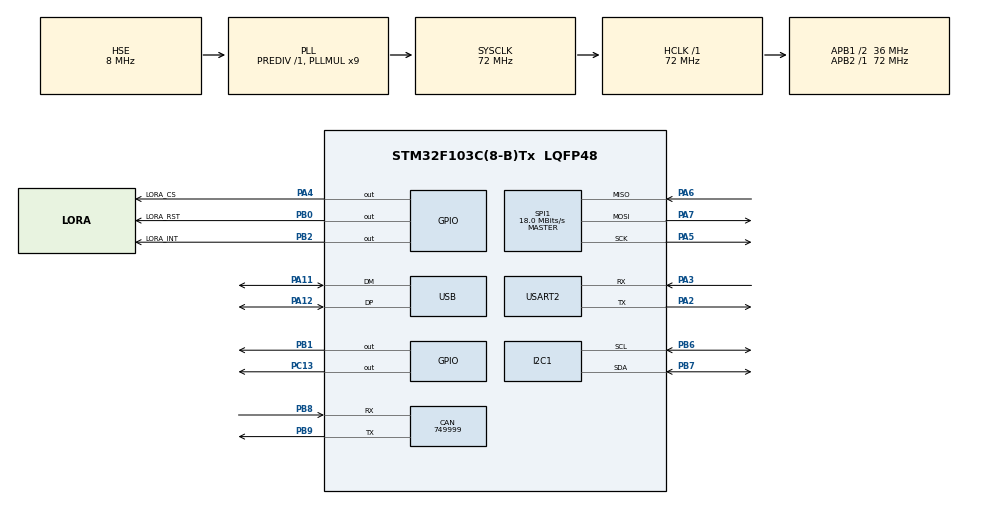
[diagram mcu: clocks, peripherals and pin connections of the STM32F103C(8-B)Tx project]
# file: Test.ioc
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CAN.CalculateBaudRate=749999
CAN.CalculateTimeBit=1333
CAN.CalculateTimeQuantum=444.44444444444446
FREERTOS.Tasks01=defaultTask,0,128,StartDefaultTask,Default,NULL,Dynamic,NULL,NULL
Mcu.Family=STM32F1
Mcu.Name=STM32F103C(8-B)Tx
Mcu.Package=LQFP48
NVIC.PriorityGroup=NVIC_PRIORITYGROUP_4
NVIC.TIM1_UP_IRQn=true\:15\:0\:false\:false\:true\:false\:false\:true\:true
NVIC.TimeBase=TIM1_UP_IRQn
NVIC.TimeBaseIP=TIM1
NVIC.USB_LP_CAN1_RX0_IRQn=true\:5\:0\:false\:false\:true\:true\:false\:true\:true
PA11.Mode=Device
PA11.Signal=USB_DM
PA12.Mode=Device
PA12.Signal=USB_DP
PA13.Mode=Serial_Wire
PA13.Signal=SYS_JTMS-SWDIO
PA14.Mode=Serial_Wire
PA14.Signal=SYS_JTCK-SWCLK
PA2.Mode=Asynchronous
PA2.Signal=USART2_TX
PA3.Mode=Asynchronous
PA3.Signal=USART2_RX
PA4.GPIO_Label=LORA_CS
PA4.Signal=GPIO_Output
PA5.Mode=Full_Duplex_Master
PA5.Signal=SPI1_SCK
PA6.Mode=Full_Duplex_Master
PA6.Signal=SPI1_MISO
PA7.Mode=Full_Duplex_Master
PA7.Signal=SPI1_MOSI
PB0.GPIO_Label=LORA_RST
PB0.Signal=GPIO_Output
PB1.Signal=GPIO_Output
PB2.GPIO_Label=LORA_INT
PB2.Signal=GPIO_Output
PB6.Mode=I2C
PB6.Signal=I2C1_SCL
PB7.Mode=I2C
PB7.Signal=I2C1_SDA
PB8.Mode=CAN_Activate
PB8.Signal=CAN_RX
PB9.Mode=CAN_Activate
PB9.Signal=CAN_TX
PC13-TAMPER-RTC.Signal=GPIO_Output
PD0-OSC_IN.Mode=HSE-External-Oscillator
PD0-OSC_IN.Signal=RCC_OSC_IN
PD1-OSC_OUT.Mode=HSE-External-Oscillator
PD1-OSC_OUT.Signal=RCC_OSC_OUT
ProjectManager.HeapSize=0x200
ProjectManager.StackSize=0x400
ProjectManager.TargetToolchain=STM32CubeIDE
RCC.AHBFreq_Value=72000000
RCC.APB1CLKDivider=RCC_HCLK_DIV2
RCC.APB1Freq_Value=36000000
RCC.APB1TimFreq_Value=72000000
RCC.APB2Freq_Value=72000000
RCC.APB2TimFreq_Value=72000000
RCC.HCLKFreq_Value=72000000
RCC.PLLMUL=RCC_PLL_MUL9
RCC.SYSCLKFreq_VALUE=72000000
RCC.SYSCLKSource=RCC_SYSCLKSOURCE_PLLCLK
RCC.USBFreq_Value=48000000
RCC.USBPrescaler=RCC_USBCLKSOURCE_PLL_DIV1_5
SPI1.BaudRatePrescaler=SPI_BAUDRATEPRESCALER_4
SPI1.CalculateBaudRate=18.0 MBits/s
SPI1.Direction=SPI_DIRECTION_2LINES
SPI1.Mode=SPI_MODE_MASTER
SPI1.VirtualType=VM_MASTER
USART2.VirtualMode=VM_ASYNC
USB_DEVICE.CLASS_NAME_FS=CDC
USB_DEVICE.VirtualMode=Cdc
USB_DEVICE.VirtualModeFS=Cdc_FS
VP_FREERTOS_VS_CMSIS_V1.Mode=CMSIS_V1
VP_SYS_VS_tim1.Mode=TIM1
VP_USB_DEVICE_VS_USB_DEVICE_CDC_FS.Mode=CDC_FS
board=custom

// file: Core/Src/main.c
/* USER CODE BEGIN Header */
/**
  ******************************************************************************
  * @file           : main.c
  * @brief          : Main program body
  ******************************************************************************
  * @attention
  *
  * Copyright (c) 2023 STMicroelectronics.
  * All rights reserved.
  *
  * This software is licensed under terms that can be found in the LICENSE file
  * in the root directory of this software component.
  * If no LICENSE file comes with this software, it is provided AS-IS.
  *
  ******************************************************************************
  */
/* USER CODE END Header */
#include "main.h"
#include "cmsis_os.h"
#include "usb_device.h"

CAN_HandleTypeDef hcan;

I2C_HandleTypeDef hi2c1;

SPI_HandleTypeDef hspi1;

UART_HandleTypeDef huart2;

osThreadId defaultTaskHandle;

void SystemClock_Config(void);
static void MX_GPIO_Init(void);
static void MX_CAN_Init(void);
static void MX_I2C1_Init(void);
static void MX_SPI1_Init(void);
static void MX_USART2_UART_Init(void);
void StartDefaultTask(void const * argument);

/* USER CODE BEGIN 0 */
uint8_t data[10000];
uint8_t count=0;
void HAL_UART_TxCpltCallback(UART_HandleTypeDef *huart)
{
	//HAL_UART_Transmit_IT(huart, data, sizeof(data));
}
/* USER CODE END 0 */

int main(void)
{

  /* MCU Configuration--------------------------------------------------------*/

  /* Reset of all peripherals, Initializes the Flash interface and the Systick. */
  HAL_Init();

  /* Configure the system clock */
  SystemClock_Config();

  /* Initialize all configured peripherals */
  MX_GPIO_Init();
  MX_CAN_Init();
  MX_I2C1_Init();
  MX_SPI1_Init();
  MX_USART2_UART_Init();
  /* USER CODE BEGIN 2 */
  //data[0] = "HELLO WORLD\r\n";
  for(int i = 0;i<10000;i++)
  {
	  data[i] = 'x';
  }
  HAL_UART_Transmit_IT(&huart1,data, sizeof(data));
  /* USER CODE END 2 */

  /* Create the thread(s) */
  /* definition and creation of defaultTask */
  osThreadDef(defaultTask, StartDefaultTask, osPriorityNormal, 0, 128);
  defaultTaskHandle = osThreadCreate(osThread(defaultTask), NULL);

  /* Start scheduler */
  osKernelStart();

  /* We should never get here as control is now taken by the scheduler */
  /* Infinite loop */
  while (1)
  {

    /* USER CODE BEGIN 3 */
	  HAL_GPIO_TogglePin(GPIOC, GPIO_PIN_13);
	  HAL_Delay(250);
	  count++ ;
	  if((count%20)==0)
		  HAL_UART_Transmit_IT(&huart1, data, sizeof(data));
  }
  /* USER CODE END 3 */
}

void SystemClock_Config(void)
{
  RCC_OscInitTypeDef RCC_OscInitStruct = {0};
  RCC_ClkInitTypeDef RCC_ClkInitStruct = {0};
  RCC_PeriphCLKInitTypeDef PeriphClkInit = {0};

  /** Initializes the RCC Oscillators according to the specified parameters
  * in the RCC_OscInitTypeDef structure.
  */
  RCC_OscInitStruct.OscillatorType = RCC_OSCILLATORTYPE_HSE;
  RCC_OscInitStruct.HSEState = RCC_HSE_ON;
  RCC_OscInitStruct.HSEPredivValue = RCC_HSE_PREDIV_DIV1;
  RCC_OscInitStruct.HSIState = RCC_HSI_ON;
  RCC_OscInitStruct.PLL.PLLState = RCC_PLL_ON;
  RCC_OscInitStruct.PLL.PLLSource = RCC_PLLSOURCE_HSE;
  RCC_OscInitStruct.PLL.PLLMUL = RCC_PLL_MUL9;
  if (HAL_RCC_OscConfig(&RCC_OscInitStruct) != HAL_OK)
  {
    Error_Handler();
  }

  /** Initializes the CPU, AHB and APB buses clocks
  */
  RCC_ClkInitStruct.ClockType = RCC_CLOCKTYPE_HCLK|RCC_CLOCKTYPE_SYSCLK
                              |RCC_CLOCKTYPE_PCLK1|RCC_CLOCKTYPE_PCLK2;
  RCC_ClkInitStruct.SYSCLKSource = RCC_SYSCLKSOURCE_PLLCLK;
  RCC_ClkInitStruct.AHBCLKDivider = RCC_SYSCLK_DIV1;
  RCC_ClkInitStruct.APB1CLKDivider = RCC_HCLK_DIV2;
  RCC_ClkInitStruct.APB2CLKDivider = RCC_HCLK_DIV1;

  if (HAL_RCC_ClockConfig(&RCC_ClkInitStruct, FLASH_LATENCY_2) != HAL_OK)
  {
    Error_Handler();
  }
  PeriphClkInit.PeriphClockSelection = RCC_PERIPHCLK_USB;
  PeriphClkInit.UsbClockSelection = RCC_USBCLKSOURCE_PLL_DIV1_5;
  if (HAL_RCCEx_PeriphCLKConfig(&PeriphClkInit) != HAL_OK)
  {
    Error_Handler();
  }
}

static void MX_CAN_Init(void)
{

  hcan.Instance = CAN1;
  hcan.Init.Prescaler = 16;
  hcan.Init.Mode = CAN_MODE_NORMAL;
  hcan.Init.SyncJumpWidth = CAN_SJW_1TQ;
  hcan.Init.TimeSeg1 = CAN_BS1_1TQ;
  hcan.Init.TimeSeg2 = CAN_BS2_1TQ;
  hcan.Init.TimeTriggeredMode = DISABLE;
  hcan.Init.AutoBusOff = DISABLE;
  hcan.Init.AutoWakeUp = DISABLE;
  hcan.Init.AutoRetransmission = DISABLE;
  hcan.Init.ReceiveFifoLocked = DISABLE;
  hcan.Init.TransmitFifoPriority = DISABLE;
  if (HAL_CAN_Init(&hcan) != HAL_OK)
  {
    Error_Handler();
  }

}

static void MX_I2C1_Init(void)
{

  hi2c1.Instance = I2C1;
  hi2c1.Init.ClockSpeed = 100000;
  hi2c1.Init.DutyCycle = I2C_DUTYCYCLE_2;
  hi2c1.Init.OwnAddress1 = 0;
  hi2c1.Init.AddressingMode = I2C_ADDRESSINGMODE_7BIT;
  hi2c1.Init.DualAddressMode = I2C_DUALADDRESS_DISABLE;
  hi2c1.Init.OwnAddress2 = 0;
  hi2c1.Init.GeneralCallMode = I2C_GENERALCALL_DISABLE;
  hi2c1.Init.NoStretchMode = I2C_NOSTRETCH_DISABLE;
  if (HAL_I2C_Init(&hi2c1) != HAL_OK)
  {
    Error_Handler();
  }

}

static void MX_SPI1_Init(void)
{

  /* SPI1 parameter configuration*/
  hspi1.Instance = SPI1;
  hspi1.Init.Mode = SPI_MODE_MASTER;
  hspi1.Init.Direction = SPI_DIRECTION_2LINES;
  hspi1.Init.DataSize = SPI_DATASIZE_8BIT;
  hspi1.Init.CLKPolarity = SPI_POLARITY_LOW;
  hspi1.Init.CLKPhase = SPI_PHASE_1EDGE;
  hspi1.Init.NSS = SPI_NSS_SOFT;
  hspi1.Init.BaudRatePrescaler = SPI_BAUDRATEPRESCALER_4;
  hspi1.Init.FirstBit = SPI_FIRSTBIT_MSB;
  hspi1.Init.TIMode = SPI_TIMODE_DISABLE;
  hspi1.Init.CRCCalculation = SPI_CRCCALCULATION_DISABLE;
  hspi1.Init.CRCPolynomial = 10;
  if (HAL_SPI_Init(&hspi1) != HAL_OK)
  {
    Error_Handler();
  }

}

static void MX_USART2_UART_Init(void)
{

  huart2.Instance = USART2;
  huart2.Init.BaudRate = 115200;
  huart2.Init.WordLength = UART_WORDLENGTH_8B;
  huart2.Init.StopBits = UART_STOPBITS_1;
  huart2.Init.Parity = UART_PARITY_NONE;
  huart2.Init.Mode = UART_MODE_TX_RX;
  huart2.Init.HwFlowCtl = UART_HWCONTROL_NONE;
  huart2.Init.OverSampling = UART_OVERSAMPLING_16;
  if (HAL_UART_Init(&huart2) != HAL_OK)
  {
    Error_Handler();
  }

}

static void MX_GPIO_Init(void)
{
  GPIO_InitTypeDef GPIO_InitStruct = {0};

  /* GPIO Ports Clock Enable */
  __HAL_RCC_GPIOC_CLK_ENABLE();
  __HAL_RCC_GPIOD_CLK_ENABLE();
  __HAL_RCC_GPIOA_CLK_ENABLE();
  __HAL_RCC_GPIOB_CLK_ENABLE();

  /*Configure GPIO pin Output Level */
  HAL_GPIO_WritePin(GPIOC, GPIO_PIN_13, GPIO_PIN_RESET);

  /*Configure GPIO pin Output Level */
  HAL_GPIO_WritePin(LORA_CS_GPIO_Port, LORA_CS_Pin, GPIO_PIN_RESET);

  /*Configure GPIO pin Output Level */
  HAL_GPIO_WritePin(GPIOB, LORA_RST_Pin|GPIO_PIN_1|LORA_INT_Pin, GPIO_PIN_RESET);

  /*Configure GPIO pin : PC13 */
  GPIO_InitStruct.Pin = GPIO_PIN_13;
  GPIO_InitStruct.Mode = GPIO_MODE_OUTPUT_PP;
  GPIO_InitStruct.Pull = GPIO_NOPULL;
  GPIO_InitStruct.Speed = GPIO_SPEED_FREQ_LOW;
  HAL_GPIO_Init(GPIOC, &GPIO_InitStruct);

  /*Configure GPIO pin : LORA_CS_Pin */
  GPIO_InitStruct.Pin = LORA_CS_Pin;
  GPIO_InitStruct.Mode = GPIO_MODE_OUTPUT_PP;
  GPIO_InitStruct.Pull = GPIO_NOPULL;
  GPIO_InitStruct.Speed = GPIO_SPEED_FREQ_LOW;
  HAL_GPIO_Init(LORA_CS_GPIO_Port, &GPIO_InitStruct);

  /*Configure GPIO pins : LORA_RST_Pin PB1 LORA_INT_Pin */
  GPIO_InitStruct.Pin = LORA_RST_Pin|GPIO_PIN_1|LORA_INT_Pin;
  GPIO_InitStruct.Mode = GPIO_MODE_OUTPUT_PP;
  GPIO_InitStruct.Pull = GPIO_NOPULL;
  GPIO_InitStruct.Speed = GPIO_SPEED_FREQ_LOW;
  HAL_GPIO_Init(GPIOB, &GPIO_InitStruct);

}

void StartDefaultTask(void const * argument)
{
  /* init code for USB_DEVICE */
  MX_USB_DEVICE_Init();
  for(;;)
  {
    osDelay(1);
  }
}

void HAL_TIM_PeriodElapsedCallback(TIM_HandleTypeDef *htim)
{
  if (htim->Instance == TIM1) {
    HAL_IncTick();
  }
}

void Error_Handler(void)
{
  __disable_irq();
  while (1)
  {
  }
}
